# nrf7140_wificore register map
Vendor: Nordic Semiconductor; Series: nRF71; File version: 1
Registers are 32-bit, read-write, reset 0x0 unless marked. A register's access mark holds for its fields unless they carry their own. Offsets are from the block's base; [hi:lo] are bit positions; lines under a group give offsets from that group; {n}, {i} and the like mark numbered series.

## RPUSYS (part 1 of 3) — RPUPBUS
Base 0x48080000; alternate view of RPUMAC
0x00 RPU_INTERRUPT_CTRL group — Unspecified
  0x00 HWSTATEXT0 ro — RPU INTERRUPT CTRL HWSTATEXT0
    [31:0] IRQHWSTAT0 — When set to '1', this indicates assertion of internal interrupts 31..0.
  0x04 HWSTATEXT1 ro — RPU INTERRUPT CTRL HWSTATEXT1
    [31:0] IRQHWSTAT1 — When set to '1', this indicates assertion of internal interrupts 63..32.
  0x08 HWSTATEXT2 ro — RPU INTERRUPT CTRL HWSTATEXT2
    [31:0] IRQHWSTAT2 — When set to '1', this indicates assertion of external interrupts 31..0.
  0x0C HWSTATEXT3 ro — RPU INTERRUPT CTRL HWSTATEXT3
    [31:0] IRQHWSTAT3 — When set to '1', this indicates assertion of external interrupts 63..32.
  {0x200+4j} HWVECEXT[{j}] (j=0..127) — Description collection: RPU INTERRUPT CTRL HWVECEXT
    [5:0] IRQHWVEC — Vectors the trigger from the SPI Slave interrupt,where 0=disabled,1..(4 x NUM_MCU) = MCU0, MCU1 etc (where each of MCUn is a 4-bit vector),(4 x NUM_MCU +1)..((4 x NUM_MCU) + (4 x NUM_ECU)) = ECU0, ECU1 etc (where each of ECUn is a 4-bit vector.
0x1000 RPU_LOGGING group — Unspecified
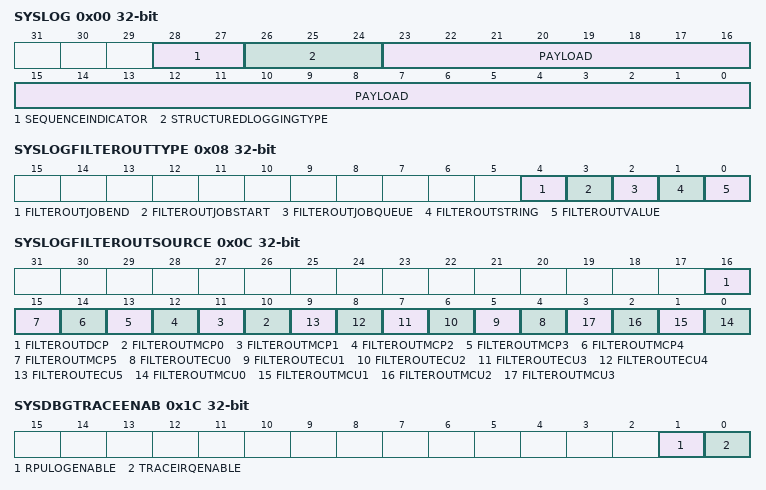
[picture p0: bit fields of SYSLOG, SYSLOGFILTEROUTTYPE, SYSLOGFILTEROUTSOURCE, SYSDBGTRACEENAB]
  0x00 SYSLOG — RPU LOGGING SYS LOG
    [28:27] SEQUENCEINDICATOR — Sequence Indicator (Header bits 5:4).
    [26:24] STRUCTUREDLOGGINGTYPE — Structured Logging Type (Header bits 2:0).
    [23:0] PAYLOAD — 24-bit payload.
  0x04 SYSLOGSTATUS — RPU LOGGING SYS LOG STATUS
    [0] OVERFLOW — Set to 1 when an overflow occurs. This is a sticky but which should be cleared by writing any value to this bit.
  0x08 SYSLOGFILTEROUTTYPE — RPU LOGGING SYS LOG FILTEROUT TYPE
    [4] FILTEROUTJOBEND — When set to 1, filters out logging items of type 'Job End'.
    [3] FILTEROUTJOBSTART — When set to 1, filters out logging items of type 'Job Start'.
    [2] FILTEROUTJOBQUEUE — When set to 1, filters out logging items of type 'Job Queue'.
    [1] FILTEROUTSTRING — When set to 1, filters out logging items of type 'String'.
    [0] FILTEROUTVALUE — When set to 1, filters out logging items of type 'Value'.
  0x0C SYSLOGFILTEROUTSOURCE — RPU LOGGING SYS LOG FILTEROUT SOURCE
    [16] FILTEROUTDCP — When set to 1, filters out logging from DCP.
    [n+10] FILTEROUTMCP{n} (n=0..5) — When set to 1, filters out logging from MCP{n}.
    [n+4] FILTEROUTECU{n} (n=0..5) — When set to 1, filters out logging from ECU{n}.
    [n] FILTEROUTMCU{n} (n=0..3) — When set to 1, filters out logging from MCU{n}.
  0x10 SYSTIMEBASELO — RPU LOGGING SYS TIME BASE LO
    [31:0] TIMEBASELO — Bottom 32 bits of the Time Base. SW can write to thise register, but only if TRACE_TIMESTAMP_ENABLE = 0.
  0x14 SYSTIMEBASEHI — RPU LOGGING SYS TIME BASE HI
    [3:0] TIMEBASEHI — Top 4 bits of the Time Base. SW can write to thise register, but only if TRACE_TIMESTAMP_ENABLE = 0.
  0x18 SYSDBGTRACESTAT — RPU LOGGING SYS DBG TRACE STAT
    [0] TRACEIRQSTATUS — Debug trace interrupt status.Latched high when TRACE_POINTER = TRACE_LENGTH / 2.Can be forced high by writing 1 to this register for debug purposes (to test interrupt connectivity in hardware and software).
  0x1C SYSDBGTRACEENAB — RPU LOGGING SYS DBG TRACE ENAB
    [1] RPULOGENABLE — Enables RPU logging. By default it is disabled.
    [0] TRACEIRQENABLE — Debug trace interrupt enable for channel.ANDed with TRACE_IRQ_STATUS before generating IRQ output from block.
  0x20 SYSDBGTRACECLR — RPU LOGGING SYS DBG TRACE CLR
    [0] TRACEIRQCLEAR — Debug trace interrupt acknowledge/clear for channel.Write 1 to clear TRACE_IRQ_STATUS.Writing 0 has no effect.
  0x24 SYSDBGTRACEADD — RPU LOGGING SYS DBG TRACE ADD
    [19:1] TRACEBASEADDRESS — 48-bit word-aligned based address in global memory at which to start writing the trace of values logged by the DCP.Two 24-bit items are logged:1. 24-bit word containing a timestamp in bits [23:6] andDCP channel ID in bits [5:0].2. 24-bit MA register value.
  0x28 SYSDBGTRACELEN — RPU LOGGING SYS DBG TRACE LEN
    [19:1] TRACELENGTH — 48-bit word-aligned trace length - 1.Trace writes wrap at TRACE_BASE_ADDRESS + TRACE_LENGTH back to TRACE_BASE_ADDRESS.
  0x2C SYSDBGTRACEPTR — RPU LOGGING SYS DBG TRACE PTR
    [19:1] TRACEPOINTER — 48-bit word-aligned pointer offset from TRACE_BASE_ADDRESS for last trace write.Automatically increments as each trace item is written and wraps back to 0 at TRACE_LENGTH.
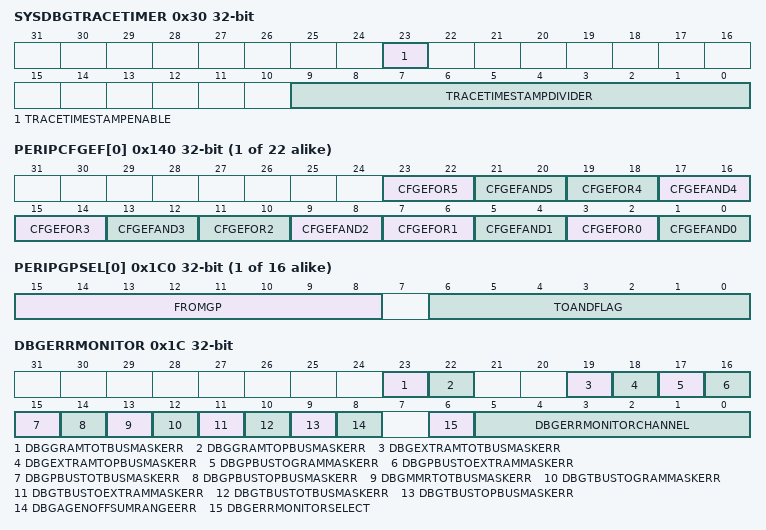
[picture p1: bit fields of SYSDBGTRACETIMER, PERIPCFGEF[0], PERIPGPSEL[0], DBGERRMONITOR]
  0x30 SYSDBGTRACETIMER — RPU LOGGING SYS DBG TRACE TIMER
    [23] TRACETIMESTAMPENABLE
      0=Timestamp timer disabled (power saving mode); 1=Timestamp timer enabled
    [9:0] TRACETIMESTAMPDIVIDER — Timestamp period - 1 in core clocks
0x3000 UCC_EFS group — Unspecified
  {0x0+4j} FLAGSTATEK[{j}] (j=0..63) ro — Description collection: UCC EFS FLAG STATE K
    [23:8] FLAGSTATEK150 — The states of Event Flags 16*K + (15 downto 0)
  {0x100+4j} CFGQUEUEORGP[{j}] (j=0..10) — Description collection: UCC EFS CFG QUEUE OR GP
    [23:0] CFGQUEUEORGP — Select 0: queue or 1: gp ,24*K + (23 downto 0)
  0x12C GPNUMACTIVESEL — UCC EFS GP NUM ACTIVE SEL
    [4:0] GPNUMACTIVESEL — The max number of active selectors in this instance of the Event Flag System (1 to 16).
  {0x140+4j} PERIPCFGEF[{j}] (j=0..21) — Description collection: UCC EFS PERIP CFG EF
    [4n+3:4n+2] CFGEFOR{n} (n=1..5) — OR gate configuration 6N+{n}
    [4n+1:4n] CFGEFAND{n} (n=1..5) — AND gate configuration 6N+{n}
    [3:2] CFGEFOR0 — OR gate configuration 6N:
      0=DisabledZero; 1=PassThroughUpper; 2=PassThorughLower; 3=OrUpperAndLower
    [1:0] CFGEFAND0 — AND gate configuration 6N:
      0=DisabledZero; 1=PassThroughUpper; 2=PassThorughLower; 3=AndUpperAndLower
  {0x1C0+4j} PERIPGPSEL[{j}] (j=0..15) — Description collection: UCC EFS PERIP GP SEL
    [15:8] FROMGP — From GP mux value
    [6:0] TOANDFLAG — To AND flag demux value
  {0x200+4j} OFXVECTOR[{j}] (j=0..127) ro — Description collection: UCC EFS OFX VECTOR
    [8:0] OFHIGHESTVECTOR — The VECTOR value associated with the highest priority asserted Event Flag in OFx.
  {0x400+4j} MCP0FLAGSOURCEN[{j}] (j=0..0) — Description collection: UCC EFS MCP0 FLAG SOURCEN
    [6:0] MCP0FLAGSOURCE — The OR flag number that releases MCP0 from WAIT.
  {0x420+4j} MCP1FLAGSOURCEN[{j}] (j=0..0) — Description collection: UCC EFS MCP1 FLAG SOURCEN
    [6:0] MCP1FLAGSOURCE — The OR flag number that releases MCP1 from WAIT.
  {0x440+4j} MCP2FLAGSOURCEN[{j}] (j=0..0) — Description collection: UCC EFS MCP2 FLAG SOURCEN
    [6:0] MCP2FLAGSOURCE — The OR flag number that releases MCP2 from WAIT.
  {0x460+4j} MCP3FLAGSOURCEN[{j}] (j=0..0) — Description collection: UCC EFS MCP3 FLAG SOURCEN
    [6:0] MCP3FLAGSOURCE — The OR flag number that releases MCP3 from WAIT.
  {0x480+4j} MCP4FLAGSOURCEN[{j}] (j=0..0) — Description collection: UCC EFS MCP4 FLAG SOURCEN
    [6:0] MCP4FLAGSOURCE — The OR flag number that releases MCP4 from WAIT.
  {0x4A0+4j} MCP5FLAGSOURCEN[{j}] (j=0..0) — Description collection: UCC EFS MCP5 FLAG SOURCEN
    [6:0] MCP5FLAGSOURCE — The OR flag number that releases MCP5 from WAIT.
  0x500 MCUINTERRUPTSOURCE — UCC EFS MCU INTERRUPT SOURCE
    [6:0] MCUFLAGSOURCE — The OR flag number that drives an MCU interrupt
  0x504 HPINTERRUPT1SOURCE — UCC EFS HP INTERRUPT1 SOURCE
    [6:0] HPFLAG1SOURCE — The OR flag number that drives High Priority interrupt 1
  0x508 ECUINTERRUPTSOURCE — UCC EFS ECU INTERRUPT SOURCE
    [6:0] ECUFLAGSOURCE — The OR flag number that drives ECU interrupt
  0x51C MCU2INTERRUPTSOURCE — UCC EFS MCU2 INTERRUPT SOURCE
    [6:0] MCU2FLAGSOURCE — The OR flag number that drives an MCU2 interrupt
  0x520 HPINTERRUPT2SOURCE — UCC EFS HP INTERRUPT2 SOURCE
    [6:0] HPFLAG2SOURCE — The OR flag number that drives High Priority interrupt 2
  0x600 MCUINTERRUPTSTAT — UCC EFS MCU INTERRUPT STAT
    [0] MCUIRQSTATUS — MCU interrupt status.Latched high when OF[MCU_FLAG_SOURCE] == 1.Can be forced high by writing 1 to this register for debug purposes (to test interrupt connectivity in hardware and software).
  0x604 MCUINTERRUPTENAB — UCC EFS MCU INTERRUPT ENAB
    [0] MCUIRQENABLE — MCU interrupt enable.ANDed with MCU_IRQ_STATUS before generating IRQ output from block.
  0x608 MCUINTERRUPTCLR — UCC EFS MCU INTERRUPT CLR
    [0] MCUIRQCLEAR — MCU interrupt acknowledge/clear.Write 1 to clear MCU_IRQ_STATUS.Writing 0 has no effect.Read returns 1 during clear hold-off delay.
  0x60C MCUINTERRUPTENABHOLDOFF — UCC EFS MCU INTERRUPT ENAB HOLDOFF
    [8:0] MCUIRQENABLEHOLDOFF — MCU interrupt enable clear hold-off delay.Defaults to NUM_AND_FLAGS + NUM_OR_FLAGS.Delay required to account for propogation of cleared source event through cascaded gate delaywithin EFS, to allow the interrupt enable to be toggled to generate an MCU edge-sensitive interruptfor additional events whilst preventing surplus interrupt generation.
  0x610 MCUINTERRUPTCLRHOLDOFF — UCC EFS MCU INTERRUPT CLR HOLDOFF
    [8:0] MCUIRQCLEARHOLDOFF — MCU interrupt clear hold-off delay.Defaults to NUM_AND_FLAGS + NUM_OR_FLAGS.Delay required to account for propogation of cleared source event through cascaded gate delaywithin EFS, to prevent surplus interrupt generation.
  0x620 HPINTERRUPT1STAT — UCC EFS HP INTERRUPT1 STAT
    [0] HPIRQ1STATUS — High priority interrupt 1 status.IRQ[n] latched high when OF[HP_FLAGn_SOURCE] == 1.Can be forced high by writing 1 to this register for debug purposes (to test interrupt connectivity in hardware and software).
  0x624 HPINTERRUPT1ENAB — UCC EFS HP INTERRUPT1 ENAB
    [0] HPIRQ1ENABLE — High priority interrupt 1 enable.ANDed with HP_IRQ1_STATUS before generating IRQ output from block.
  0x628 HPINTERRUPT1CLR — UCC EFS HP INTERRUPT1 CLR
    [0] HPIRQ1CLEAR — High priority interrupt 1 acknowledge/clear.Write 1 to clear HP_IRQ1_STATUS.Writing 0 has no effect.Read returns 1 during clear hold-off delay.
  0x62C ECUINTERRUPTSTAT — UCC EFS ECU INTERRUPT STAT
    [0] ECUIRQSTATUS — ECU interrupt status.IRQ[n] latched high when OF[ECU_FLAGn_SOURCE] == 1.Can be forced high by writing 1 to this register for debug purposes (to test interrupt connectivity in hardware and software).
  0x630 ECUINTERRUPTENAB — UCC EFS ECU INTERRUPT ENAB
    [0] ECUIRQENABLE — ECU interrupt enable.ANDed with ECU_IRQ_STATUS before generating IRQ output from block.
  0x634 ECUINTERRUPTCLR — UCC EFS ECU INTERRUPT CLR
    [0] ECUIRQCLEAR — ECU interrupt acknowledge/clear.Write 1 to clear ECU_IRQ_STATUS.Writing 0 has no effect.Read returns 1 during clear hold-off delay.
  0x638 ECUINTERRUPTENABHOLDOFF — UCC EFS ECU INTERRUPT ENAB HOLDOFF
    [8:0] ECUIRQENABLEHOLDOFF — ECU interrupt enable clear hold-off delay.Defaults to NUM_AND_FLAGS + NUM_OR_FLAGS.Delay required to account for propogation of cleared source event through cascaded gate delaywithin EFS, to allow the interrupt enable to be toggled to generate an ECU edge-sensitive interruptfor additional events whilst preventing surplus interrupt generation.
  0x63C ECUINTERRUPTCLRHOLDOFF — UCC EFS ECU INTERRUPT CLR HOLDOFF
    [8:0] ECUIRQCLEARHOLDOFF — ECU interrupt clear hold-off delay.Defaults to NUM_AND_FLAGS + NUM_OR_FLAGS.Delay required to account for propogation of cleared source event through cascaded gate delaywithin EFS, to prevent surplus interrupt generation.
  0x640 HPINTERRUPTENABHOLDOFF — UCC EFS HP INTERRUPT ENAB HOLDOFF
    [8:0] HPIRQENABLEHOLDOFF — High priority interrupt enable clear hold-off delay.Defaults to NUM_AND_FLAGS + NUM_OR_FLAGS.Delay required to account for propogation of cleared source event through cascaded gate delaywithin EFS, to allow the interrupt enable to be toggled to generate an HP edge-sensitive interruptfor additional events whilst preventing surplus interrupt generation.
  0x644 HPINTERRUPTCLRHOLDOFF — UCC EFS HP INTERRUPT CLR HOLDOFF
    [8:0] HPIRQCLEARHOLDOFF — High priority interrupt clear hold-off delay.Defaults to NUM_AND_FLAGS + NUM_OR_FLAGS.Delay required to account for propogation of cleared source event through cascaded gate delaywithin EFS, to prevent surplus interrupt generation.
  0x648 HPINTERRUPT2STAT — UCC EFS HP INTERRUPT2 STAT
    [0] HPIRQ2STATUS — High priority interrupt 2 status.IRQ[n] latched high when OF[HP_FLAGn_SOURCE] == 1.Can be forced high by writing 1 to this register for debug purposes (to test interrupt connectivity in hardware and software).
  0x64C HPINTERRUPT2ENAB — UCC EFS HP INTERRUPT2 ENAB
    [0] HPIRQ2ENABLE — High priority interrupt 2 enable.ANDed with HP_IRQ2_STATUS before generating IRQ output from block.
  0x650 HPINTERRUPT2CLR — UCC EFS HP INTERRUPT2 CLR
    [0] HPIRQ2CLEAR — High priority interrupt 2 acknowledge/clear.Write 1 to clear HP_IRQ2_STATUS.Writing 0 has no effect.Read returns 1 during clear hold-off delay.
  0x6E0 MCU2INTERRUPTSTAT — UCC EFS MCU2 INTERRUPT STAT
    [0] MCU2IRQSTATUS — MCU2 interrupt status.Latched high when OF[MCU2_FLAG_SOURCE] == 1.Can be forced high by writing 1 to this register for debug purposes (to test interrupt connectivity in hardware and software).
  0x6E4 MCU2INTERRUPTENAB — UCC EFS MCU2 INTERRUPT ENAB
    [0] MCU2IRQENABLE — MCU2 interrupt enable.ANDed with MCU2_IRQ_STATUS before generating IRQ output from block.
  0x6E8 MCU2INTERRUPTCLR — UCC EFS MCU2 INTERRUPT CLR
    [0] MCU2IRQCLEAR — MCU2 interrupt acknowledge/clear.Write 1 to clear MCU2_IRQ_STATUS.Writing 0 has no effect.Read returns 1 during clear hold-off delay.
  0xB00 BUILD0 ro — UCC EFS BUILD 0
    [4:0] BUILDMAXNUMSELECTORS — The max number of selectors in this instance of the Event Flag System (1 to 16).
  0xB04 BUILD1 ro — UCC EFS BUILD 1
    [7:0] BUILDNUMANDOR — The number of and/or gates in this instance of the Event Flag System (8 to 128).
  0xB08 BUILD2 ro — UCC EFS BUILD 2
    [9:0] BUILDMAXGFID — The highest GP flag ID number in this instance of the Event Flag System. Each GF_SEL flag can be programmed to select any GP flag from GP[0] to GP[MAX_GP_FLAG_NUM] (0 to 556).
0x5000 EDC_SYS group — Unspecified
  0x1C DBGERRMONITOR — EDC SYS DBG ERR MONITOR
    [23] DBGGRAMTOTBUSMASKERR — Partial mask only supported for final GRAM to TBus transfer
    [22] DBGGRAMTOPBUSMASKERR — Partial mask only supported for final GRAM to PBus transfer
    [19] DBGEXTRAMTOTBUSMASKERR — Partial mask only supported for final ExtRAM to TBus transfer
    [18] DBGEXTRAMTOPBUSMASKERR — Partial mask only supported for final ExtRAM to PBus transfer
    [17] DBGPBUSTOGRAMMASKERR — Partial mask only supported for final PBus to GRAM transfer
    [16] DBGPBUSTOEXTRAMMASKERR — Partial mask only supported for final PBus to ExtRAM transfer
    [15] DBGPBUSTOTBUSMASKERR — Partial mask only supported for final PBus to TBus transfer
    [14] DBGPBUSTOPBUSMASKERR — Partial mask only supported for final PBus to PBus transfer
    [13] DBGMMRTOTBUSMASKERR — Partial mask only supported for final MMR to TBus transfer
    [12] DBGTBUSTOGRAMMASKERR — Partial mask only supported for final TBus to GRAM transfer
    [11] DBGTBUSTOEXTRAMMASKERR — Partial mask only supported for final TBus to ExtRAM transfer
    [10] DBGTBUSTOTBUSMASKERR — Partial mask only supported for final TBus to TBus transfer
    [9] DBGTBUSTOPBUSMASKERR — Partial mask only supported for final TBus to PBus transfer
    [8] DBGAGENOFFSUMRANGEERR — Offset sum within address generator cannot be brought back in range
    [6] DBGERRMONITORSELECT — EDC error monitor channel select:
      0=Monitor errors on all channels; 1=Monitor error only on DBG_ERR_MONITOR_CHANNEL
    [5:0] DBGERRMONITORCHANNEL — EDC transfer channel to monitor for errors.Errors are latched and are cleared by writing to this register.
  {0x20+8j} EDCSYSCHANREGS[{j}] (j=0..63) group — Unspecified
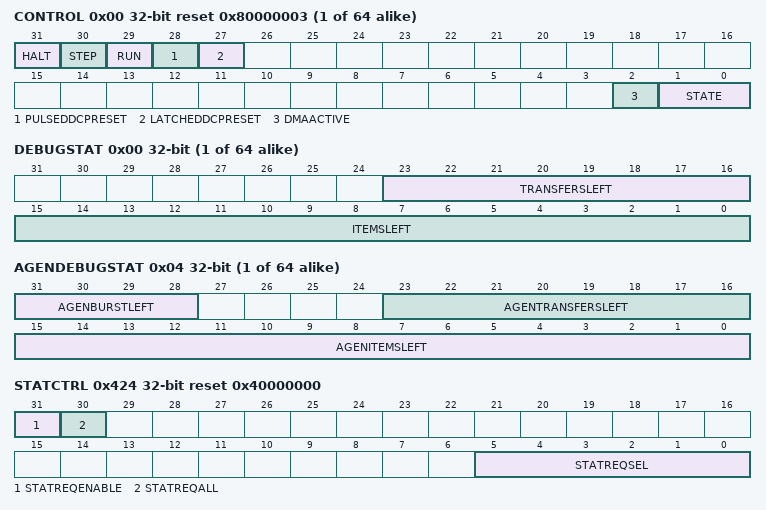
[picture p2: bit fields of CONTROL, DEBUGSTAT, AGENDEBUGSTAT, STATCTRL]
    0x00 CONTROL reset 0x80000003 — Description cluster: EDC SYS CONTROL
      [31] HALT — Set to 1 to HALT instruction stream. This bit takes precedence over STEP and RUN
      [30] STEP — Set to 1 to STEP by one instruction. This bit takes precedence over RUN
      [29] RUN — Set to 1 to start execution of the instruction stream from the current PC
      [28] PULSEDDCPRESET — Self-clearing DCP thread software reset.
      [27] LATCHEDDCPRESET — Latched DCP thread software reset.
      [2] DMAACTIVE — Read-only status:
        0=No active DMA job, instruction stream processing can continue; 1=Active DMA job, instruction stream processing stalled until completion
      [1:0] STATE — Read-only status:
        0=Running; 1=Waiting; 2=Stepping; 3=Halted
    0x04 PC — Description cluster: EDC SYS PC
      [23:0] PC — The memory address from which the next instruction will be loaded
  {0x220+8j} EDCSYSDEBUGREGS[{j}] (j=0..63) group — Unspecified
    0x00 DEBUGSTAT ro — Description cluster: EDC SYS DEBUG STAT
      [23:16] TRANSFERSLEFT — When TRANSFERS_MODE=0:The number of DMA transfers remaining in the DMA job, represented in 'natural' format.When TRANSFERS_MODE=1:ITEMS_LEFT[23:0].
      [15:0] ITEMSLEFT — The number of items remaining in each DMA transfer, represented in 'natural' format.
    0x04 AGENDEBUGSTAT ro — Description cluster: EDC SYS AGEN DEBUG STAT
      [31:28] AGENBURSTLEFT — The number of Address Generator items remaining in each burst transfer, represented in 'natural' format.
      [23:16] AGENTRANSFERSLEFT — When TRANSFERS_MODE=0:The number of Address Generator DMA transfers remaining in the DMA job, represented in 'natural' format.When TRANSFERS_MODE=1:ITEMS_LEFT[23:0].
      [15:0] AGENITEMSLEFT — The number of Address Generator items remaining in each DMA transfer, represented in 'natural' format.
  0x424 STATCTRL reset 0x40000000 — EDC SYS STAT CTRL
    [31] STATREQENABLE — Statistic accumulation control:
      0=Accumulation of statistics disabled (power saving mode); 1=AccumulationOfStatis1 (Accumulation of statistics enabled (debug mode).)
    [30] STATREQALL — Statistic accumulation request selection:
      0=Accumulate statistics for STAT_REQ_SEL requestor only; 1=AccumulateStatistics1 (Accumulate statistics across all requestors.)
    [5:0] STATREQSEL — Requestor to accumulate statistics for when STAT_REQ_ALL=0.
  0x428 DCPCYCLECNT — EDC SYS DCP CYCLE CNT
    [31:0] DCPCYCLECNT — Wrapping DCP cycle count.Write any value to clear.
  0x42C DCPISSUECNT — EDC SYS DCP ISSUE CNT
    [31:0] DCPISSUECNT — Wrapping DCP issue count.Write any value to clear.
  0x430 DCPWAITCNT — EDC SYS DCP WAIT CNT
    [31:0] DCPWAITCNT — Wrapping DCP wait count.Write any value to clear.
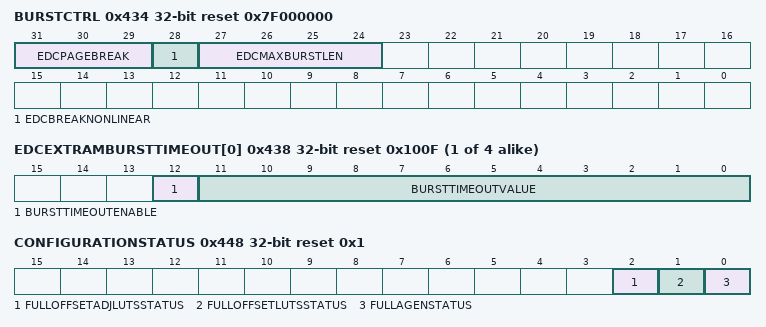
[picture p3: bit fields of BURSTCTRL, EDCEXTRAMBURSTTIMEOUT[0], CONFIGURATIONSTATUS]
  0x434 BURSTCTRL reset 0x7F000000 — EDC SYS BURST CTRL
    [31:29] EDCPAGEBREAK — Defines page boundary on which ExtRAM bursts are broken.
      0=None; 1=256ByteBoundary; 2=512ByteBoundary; 3=1 kByteBoundary (default); 4=2KbyteBoundary; 5=4KbyteBoundary; 6=8KbyteBoundary; 7=16KbyteBoundary
    [28] EDCBREAKNONLINEAR — Defines whether ExtRAM bursts are broken on non-consecutive addresses.
      0=Do not break bursts on non-linear addresses; 1=Break bursts on non-linear addresses
    [27:24] EDCMAXBURSTLEN — Maximum ExtRAM burst length '-1'. Supports bursts of maximum 16 words length.
  {0x438+4j} EDCEXTRAMBURSTTIMEOUT[{j}] (j=0..3) reset 0x100F — Description collection: EDC EXT RAM BURST TIMEOUT
    [12] BURSTTIMEOUTENABLE — When set high burst timeouts are enabled.
    [11:0] BURSTTIMEOUTVALUE — Timeout counter value
  0x448 CONFIGURATIONSTATUS ro reset 0x1 — EDC SYS CONFIGURATION STATUS
    [2] FULLOFFSETADJLUTSSTATUS — Status register bit that indicates if GRAM offset adjustment LUTs are present or not.
      0=GRAM offset adjustment LUTs not present; 1=GramOffsetAdjustment1 (GRAM offset adjustment LUTs present)
    [1] FULLOFFSETLUTSSTATUS — Status register bit that indicates if GRAM offset LUTs are present or not.
      0=GRAM offset LUTs not present; 1=GRAM offset LUTs present
    [0] FULLAGENSTATUS — Status register bit that indicates if full address generator is present or not.
      0=Full address generator not present; 1=FullAddressGenerator1 (Full address generator present)
